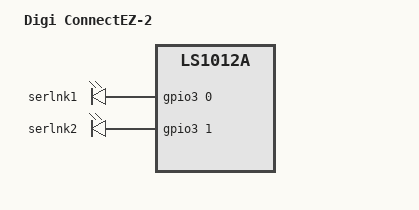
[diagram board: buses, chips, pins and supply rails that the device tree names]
// SPDX-License-Identifier: (GPL-2.0+ OR MIT)
/*
 * Device Tree Include file for Digi ConnectEZ-2.
 *
 * Copyright 2016 Freescale Semiconductor, Inc.
 * Copyright 2018 Digi Inc.
 *
 * Mingkai Hu <mingkai.hu@nxp.com>
 * Greg Ungerer <gregory.ungerer@digi.com>
 */

/dts-v1/;
#include "connectez-base.dtsi"

/ {
	model = "Digi ConnectEZ-2";
	compatible = "digi,connectez2", "digi,connectez", "fsl,ls1012a";

	leds {
		compatible = "gpio-leds";

		ser1link {
			label = "serlnk1";
			gpios = <&gpio3 0 GPIO_ACTIVE_HIGH>;
			linux,default-trigger = "none";
			default-state = "off";
		};

		ser2link {
			label = "serlnk2";
			gpios = <&gpio3 1 GPIO_ACTIVE_HIGH>;
			linux,default-trigger = "none";
			default-state = "off";
		};
	};
};
